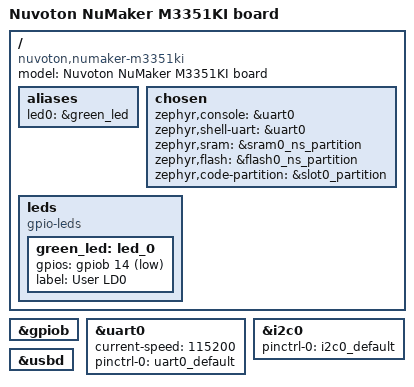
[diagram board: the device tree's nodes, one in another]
/*
 * SPDX-FileCopyrightText: Copyright (c) 2026 Nuvoton Technology Corporation
 * SPDX-License-Identifier: Apache-2.0
 */

#define NVT_DT_TZ_NSPE 1

/dts-v1/;

#include <nuvoton/m3351kjc.dtsi>
#include "numaker_m3351ki-pinctrl.dtsi"
#include "numaker_m3351ki-partition-memory.dtsi"
#include <zephyr/dt-bindings/input/input-event-codes.h>

/ {
	model = "Nuvoton NuMaker M3351KI board";
	compatible = "nuvoton,numaker-m3351ki";

	aliases {
		led0 = &green_led;
	};

	chosen {
		zephyr,console = &uart0;
		zephyr,shell-uart = &uart0;
		zephyr,sram = &sram0_ns_partition;
		zephyr,flash = &flash0_ns_partition;
		zephyr,code-partition = &slot0_partition;
	};

	leds {
		compatible = "gpio-leds";

		green_led: led_0 {
			gpios = <&gpiob 14 GPIO_ACTIVE_LOW>;
			label = "User LD0";
		};
	};
};

&gpiob {
	status = "okay";
};

&uart0 {
	current-speed = <115200>;
	pinctrl-0 = <&uart0_default>;
	pinctrl-names = "default";
	status = "okay";
};

arduino_i2c: &i2c0 {
	pinctrl-0 = <&i2c0_default>;
	pinctrl-names = "default";
	status = "okay";
};

zephyr_udc0: &usbd {
	/*
	 * Clock source defaults to HIRC, which runs at required 48MHz.
	 * Pinctrl is unneeded because pins are dedicated.
	 */
	status = "okay";
};
